# max32665 register map
Vendor: Maxim-Integrated; Series: ARMCM3; File version: 1.0
CPU: CM4 r2p1, little endian, MPU, FPU, 3 interrupt priority bits
Registers are 32-bit, read-write, reset 0x0 unless marked. A register's access mark holds for its fields unless they carry their own. Offsets are from the block's base; [hi:lo] are bit positions.

## ICC0 — Instruction Cache Controller Registers
Base 0x4002A000
Same registers: ICC1 0x4002F000
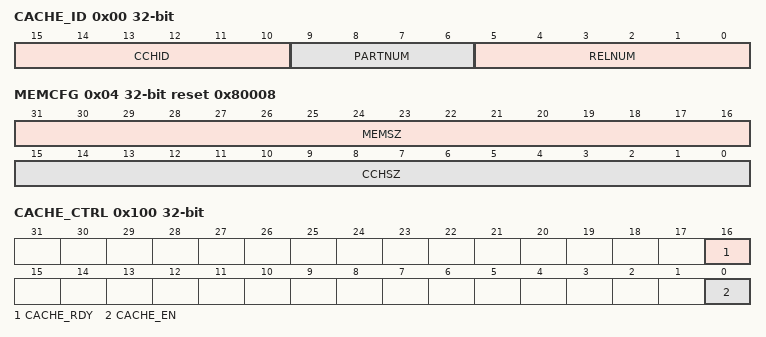
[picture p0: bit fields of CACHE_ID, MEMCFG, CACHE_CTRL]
0x00 CACHE_ID ro
  [15:10] CCHID — Cache ID. This field reflects the value of the C_ID_CACHEID configuration parameter.
  [9:6] PARTNUM — Part Number. This field reflects the value of C_ID_PART_NUMBER configuration parameter.
  [5:0] RELNUM — Release Number. Identifies the RTL release version.
0x04 MEMCFG ro reset 0x80008 — Memory Configuration Register.
  [31:16] MEMSZ — Main Memory Size. Indicates the total size, in units of 128 Kbytes, of code memory accessible to the cache controller.
  [15:0] CCHSZ — Cache Size. Indicates total size in Kbytes of cache.
0x100 CACHE_CTRL — Cache Control and Status Register.
  [16] CACHE_RDY ro — Cache Ready flag. Cleared by hardware when at any time the cache as a whole is invalidated (including a system reset). When this bit is 0, the cache is effectively in bypass mode (instruction fetches will come from main memory or from the line fill buffer). Set by hardware when the invalidate operation is complete and the cache is ready.
    0=notReady; 1=ready
  [0] CACHE_EN — Cache Enable. Controls whether the cache is bypassed or is in use. Changing the state of this bit will cause the instruction cache to be flushed and its contents invalidated.
    0=dis (Cache Bypassed. Instruction data is stored in the line fill buffer but is not written to main cache memory array.); 1=en (Cache Enabled.)
0x700 INVALIDATE — Invalidate All Registers.

## FCR — Function Control.
Base 0x40000800
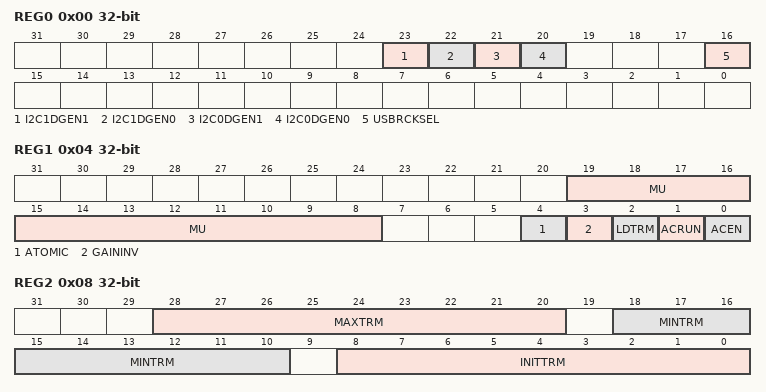
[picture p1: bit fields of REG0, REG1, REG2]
0x00 REG0 — Register 0.
  [23] I2C1DGEN1 — I2C1 SCL Pad Deglitcher enable.
    0=dis (Deglitcher disabled.); 1=en (Deglitcher enabled.)
  [22] I2C1DGEN0 — I2C1 SDA Pad Deglitcher enable.
    0=dis (Deglitcher disabled.); 1=en (Deglitcher enabled.)
  [21] I2C0DGEN1 — I2C0 SCL Pad Deglitcher enable.
    0=dis (Deglitcher disabled.); 1=en (Deglitcher enabled.)
  [20] I2C0DGEN0 — I2C0 SDA Pad Deglitcher enable.
    0=dis (Deglitcher disabled.); 1=en (Deglitcher enabled.)
  [16] USBRCKSEL — USB External Core Clock Select.
    0=sys (Generated clock from system clock.); 1=dig (Digital clock from a GPIO.)
0x04 REG1 — Register 1.
  [19:8] MU — MU value.
  [4] ATOMIC — Atomic mode.
    0=not (Not Running.); 1=run (Running.)
  [3] GAININV — Invert Gain.
    0=not (Not Running.); 1=run (Running.)
  [2] LDTRM — Load Trim.
  [1] ACRUN — Autocalibration Run.
    0=not (Not Running.); 1=run (Running.)
  [0] ACEN — Auto-calibration Enable.
    0=dis (Disabled.); 1=en (Enabled.)
0x08 REG2 — Register 2.
  [28:20] MAXTRM — Maximum Trim Setting.
  [18:10] MINTRM — Minimum Trim Setting.
  [8:0] INITTRM — Initial Trim Setting.
0x0C REG3 — Register 3.
  [7:0] DONECNT — Auto-callibration Done Counter Setting.

## OWM — 1-Wire Master Interface.
Base 0x4003D000
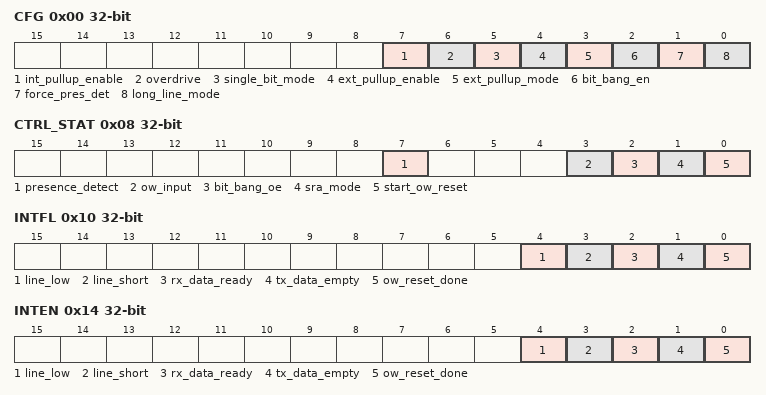
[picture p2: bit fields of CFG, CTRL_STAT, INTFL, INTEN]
0x00 CFG — 1-Wire Master Configuration.
  [7] int_pullup_enable — Enable intenral pullup.
  [6] overdrive — Enables overdrive speed for 1-Wire operations.
  [5] single_bit_mode — Enable Single Bit TX/RX Mode.
  [4] ext_pullup_enable — Enable External Pullup.
  [3] ext_pullup_mode — Provide an extra output control to control an external pullup.
  [2] bit_bang_en — Bit Bang Enable.
  [1] force_pres_det — Force Line During Presence Detect.
  [0] long_line_mode
0x04 CLK_DIV_1US — 1-Wire Master Clock Divisor.
  [7:0] divisor — Clock Divisor for 1Mhz.
0x08 CTRL_STAT — 1-Wire Master Control/Status.
  [7] presence_detect ro — Presence Pulse Detected.
  [3] ow_input ro — OW Input State.
  [2] bit_bang_oe — Bit Bang Output Enable.
  [1] sra_mode
  [0] start_ow_reset
0x0C DATA — 1-Wire Master Data Buffer.
  [7:0] tx_rx — TX/RX Buffer.
0x10 INTFL — 1-Wire Master Interrupt Flags.
  [4] line_low — OW Line Low Detected Interrupt Flag.
  [3] line_short — OW Line Short Detected Interrupt Flag.
  [2] rx_data_ready — RX Data Ready Interrupt Flag
  [1] tx_data_empty — TX Data Empty Interrupt Flag.
  [0] ow_reset_done — OW Reset Sequence Completed.
0x14 INTEN — 1-Wire Master Interrupt Enables.
  [4] line_low write-1-clears — OW Line Low Detected Interrupt Enable.
  [3] line_short write-1-clears — OW Line Short Detected Interrupt Enable.
  [2] rx_data_ready write-1-clears — Rx Data Ready Interrupt Enable.
  [1] tx_data_empty write-1-clears — Tx Data Empty Interrupt Enable.
  [0] ow_reset_done write-1-clears — OW Reset Sequence Completed.
